# SEC_MMR0_BOOT_CTRL register map
Vendor: Texas Instruments
Peripheral module from a debugger description file (folder J7ES).
Registers are 32-bit, access per field, reset 0x0 unless marked. A register's access mark holds for its fields unless they carry their own. Offsets are as the file gives them; lines under a group give offsets from that group; [hi:lo] are bit positions; {n}, {i} and the like mark numbered series; 'fields as' and 'values as' point back to an identical list; <NAME> marks a mode.

## SEC_MMR0_BOOT_CTRL
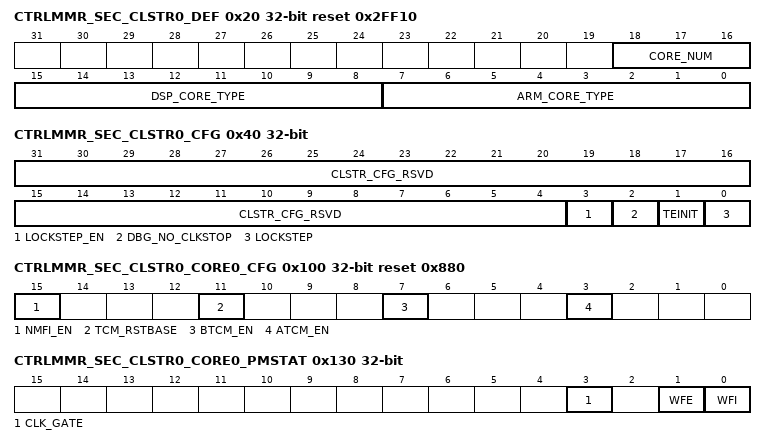
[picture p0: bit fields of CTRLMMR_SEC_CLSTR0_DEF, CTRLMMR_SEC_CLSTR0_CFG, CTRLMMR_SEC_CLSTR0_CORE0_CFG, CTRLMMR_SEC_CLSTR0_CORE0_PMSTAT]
0x20 CTRLMMR_SEC_CLSTR0_DEF ro reset 0x2FF10 — Defines the type of the processor cluster.
  [18:16] CORE_NUM — Number of cores in cluster
  [15:8] DSP_CORE_TYPE — DSP core type configuration. Not shown values are reserved. 0h - C7x 1h - C6x FFh - Not DSP
  [7:0] ARM_CORE_TYPE — ARM core type configuration. Not shown values are reserved. 0h - A53 1h - A57 10h - R5 FFh - Not ARM
0x40 CTRLMMR_SEC_CLSTR0_CFG (reset mask 0xFFFFFFF6) — Configures cluster level characteristics.
  [31:4] CLSTR_CFG_RSVD rw — Reserved for future use. Write '0' to ensure compatibility with future devices.
  [3] LOCKSTEP_EN ro — Lockstep enable. Indicates if R5 lockstep operation is supported on the device
  [2] DBG_NO_CLKSTOP rw — CPU clockstop behavior
  [1] TEINIT rw — Exception handling state at reset:
  [0] LOCKSTEP rw — When set, Core0 and Core1 operate in lockstep mode. Can only be changed if lockstep operation is supported as indicated by CLSTR0_CFG_lockstep_en = 1. If CLSTR0_CFG_lockstep_en = 0, lockstep is not supported, this bit will be read only with a value of 0.
0x100 CTRLMMR_SEC_CLSTR0_CORE0_CFG reset 0x880 — Configures the TCM and interrupt operation of R5 Core0.
  [15] NMFI_EN rw — Enable Core0 Non-Maskable Fast Interrupts when set
  [11] TCM_RSTBASE rw — Core0 A/BTCM Reset Base Address Indicator
  [7] BTCM_EN rw — Enable Core0 BTCM RAM at reset when set
  [3] ATCM_EN rw — Enable Core0 ATCM RAM at reset when set
0x110 CTRLMMR_SEC_CLSTR0_CORE0_BOOTVECT_LO reset 0x200 — Contains the lower 32 bits of the boot vector location for R5 Core0. Bits 4:0 are not used and are always 0.
  [31:7] VECT_ADDR rw — Specifies the lower 25 bits of the 41-bit vector address corresponding to Vector Table address bits[31:7]. Note bits 6:0 of the Vector Table address are always 0.
0x114 CTRLMMR_SEC_CLSTR0_CORE0_BOOTVECT_HI — Contains the lower 16 bits of the boot vector location for R5 Core0.
  [15:0] VECT_ADDR rw — Specifies the upper 16 bits of the 41-bit vector address corresponding to Vector Table address bits[47:32].
0x120 CTRLMMR_SEC_CLSTR0_CORE0_PMCTRL — Configures Cluster Core0 power state.
  [0] CORE_HALT rw — Halt Core0.When 0, indicates that Core0 is in the Halt state.
0x130 CTRLMMR_SEC_CLSTR0_CORE0_PMSTAT ro (reset mask 0xFFFFFFF4) — Shows Cluster Core0 power status.
  [3] CLK_GATE — Core0 Clock StoppedWhen 0, indicates clock stopped due to WFI or WFE state
  [1] WFE — Core0 WFE
  [0] WFI — Core0 WFI
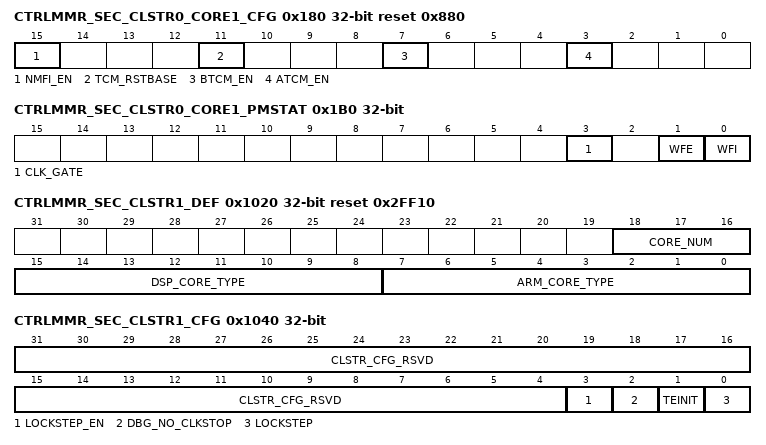
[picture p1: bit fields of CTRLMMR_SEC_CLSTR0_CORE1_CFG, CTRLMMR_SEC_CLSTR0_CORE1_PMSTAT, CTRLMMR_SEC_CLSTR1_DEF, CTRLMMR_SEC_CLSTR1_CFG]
0x180 CTRLMMR_SEC_CLSTR0_CORE1_CFG reset 0x880 — Configures the TCM and interrupt operation of R5 Core1.
  [15] NMFI_EN rw — Enable Core1 Non-Maskable Fast Interrupts when set
  [11] TCM_RSTBASE rw — Core1 A/BTCM Reset Base Address Indicator
  [7] BTCM_EN rw — Enable Core1 BTCM RAM at reset when set
  [3] ATCM_EN rw — Enable Core1 ATCM RAM at reset when set
0x190 CTRLMMR_SEC_CLSTR0_CORE1_BOOTVECT_LO reset 0x200 — Contains the lower 32 bits of the boot vector location for R5 Core1. Bits 4:0 are not used and are always 0.
  fields as CTRLMMR_SEC_CLSTR0_CORE0_BOOTVECT_LO
0x194 CTRLMMR_SEC_CLSTR0_CORE1_BOOTVECT_HI — Contains the lower 16 bits of the boot vector location for R5 Core1.
  fields as CTRLMMR_SEC_CLSTR0_CORE0_BOOTVECT_HI
0x1A0 CTRLMMR_SEC_CLSTR0_CORE1_PMCTRL — Configures Cluster Core1 power state.
  [0] CORE_HALT rw — Halt Core1.When 0, indicates that Core1 is in the Halt state.
0x1B0 CTRLMMR_SEC_CLSTR0_CORE1_PMSTAT ro (reset mask 0xFFFFFFF4) — Shows Cluster Core1 power status.
  [3] CLK_GATE — Core1 Clock StoppedWhen 0, indicates clock stopped due to WFI or WFE state
  [1] WFE — Core1 WFE
  [0] WFI — Core1 WFI
0x1020 CTRLMMR_SEC_CLSTR1_DEF ro reset 0x2FF10 — Defines the type of the processor cluster.
  fields as CTRLMMR_SEC_CLSTR0_DEF
0x1040 CTRLMMR_SEC_CLSTR1_CFG (reset mask 0xFFFFFFF6) — Configures cluster level characteristics.
  [31:4] CLSTR_CFG_RSVD rw — Reserved for future use. Write '0' to ensure compatibility with future devices.
  [3] LOCKSTEP_EN ro — Lockstep enable. Indicates if R5 lockstep operation is supported on the device
  [2] DBG_NO_CLKSTOP rw — CPU clockstop behavior
  [1] TEINIT rw — Exception handling state at reset:
  [0] LOCKSTEP rw — When set, Core0 and Core1 operate in lockstep mode. Can only be changed if lockstep operation is supported as indicated by CLSTR1_CFG_lockstep_en = 1. If CLSTR1_CFG_lockstep_en = 0, lockstep is not supported, this bit will be read only with a value of 0.
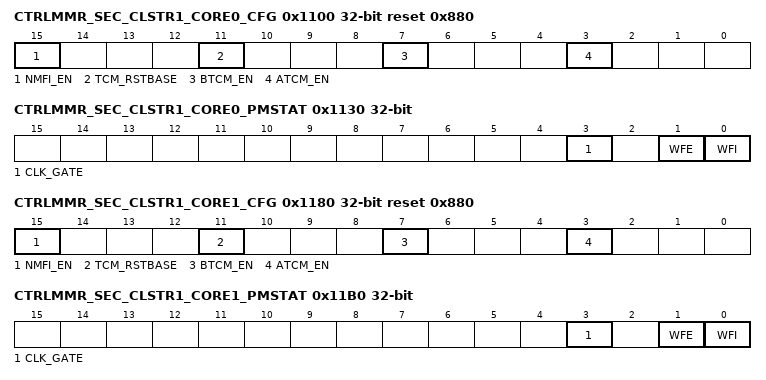
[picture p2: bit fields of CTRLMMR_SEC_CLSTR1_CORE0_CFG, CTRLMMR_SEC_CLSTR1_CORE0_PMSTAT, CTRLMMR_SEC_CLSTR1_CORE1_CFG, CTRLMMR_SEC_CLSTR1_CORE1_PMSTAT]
0x1100 CTRLMMR_SEC_CLSTR1_CORE0_CFG reset 0x880 — Configures the TCM and interrupt operation of R5 Core0.
  fields as CTRLMMR_SEC_CLSTR0_CORE0_CFG
0x1110 CTRLMMR_SEC_CLSTR1_CORE0_BOOTVECT_LO reset 0x200 — Contains the lower 32 bits of the boot vector location for R5 Core0. Bits 4:0 are not used and are always 0.
  fields as CTRLMMR_SEC_CLSTR0_CORE0_BOOTVECT_LO
0x1114 CTRLMMR_SEC_CLSTR1_CORE0_BOOTVECT_HI — Contains the lower 16 bits of the boot vector location for R5 Core0.
  fields as CTRLMMR_SEC_CLSTR0_CORE0_BOOTVECT_HI
0x1120 CTRLMMR_SEC_CLSTR1_CORE0_PMCTRL — Configures Cluster Core0 power state.
  fields as CTRLMMR_SEC_CLSTR0_CORE0_PMCTRL
0x1130 CTRLMMR_SEC_CLSTR1_CORE0_PMSTAT ro (reset mask 0xFFFFFFF4) — Shows Cluster Core0 power status.
  fields as CTRLMMR_SEC_CLSTR0_CORE0_PMSTAT
0x1180 CTRLMMR_SEC_CLSTR1_CORE1_CFG reset 0x880 — Configures the TCM and interrupt operation of R5 Core1.
  fields as CTRLMMR_SEC_CLSTR0_CORE1_CFG
0x1190 CTRLMMR_SEC_CLSTR1_CORE1_BOOTVECT_LO reset 0x200 — Contains the lower 32 bits of the boot vector location for R5 Core1. Bits 4:0 are not used and are always 0.
  fields as CTRLMMR_SEC_CLSTR0_CORE0_BOOTVECT_LO
0x1194 CTRLMMR_SEC_CLSTR1_CORE1_BOOTVECT_HI — Contains the lower 16 bits of the boot vector location for R5 Core1.
  fields as CTRLMMR_SEC_CLSTR0_CORE0_BOOTVECT_HI
0x11A0 CTRLMMR_SEC_CLSTR1_CORE1_PMCTRL — Configures Cluster Core1 power state.
  fields as CTRLMMR_SEC_CLSTR0_CORE1_PMCTRL
0x11B0 CTRLMMR_SEC_CLSTR1_CORE1_PMSTAT ro (reset mask 0xFFFFFFF4) — Shows Cluster Core1 power status.
  fields as CTRLMMR_SEC_CLSTR0_CORE1_PMSTAT
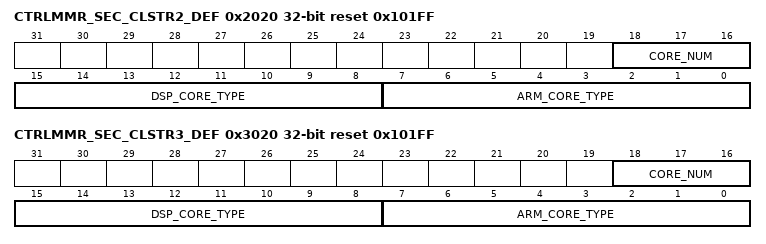
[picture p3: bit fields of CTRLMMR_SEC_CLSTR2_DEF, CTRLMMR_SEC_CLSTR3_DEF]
0x2020 CTRLMMR_SEC_CLSTR2_DEF ro reset 0x101FF — Defines the type of the processor cluster.
  fields as CTRLMMR_SEC_CLSTR0_DEF
0x2040 CTRLMMR_SEC_CLSTR2_CFG — Configures cluster level characteristics.
  [1:0] SSCLK_MODE rw — Controls the C66 clock rate for cluster logic and bus interfaces 0h - Div2 clock mode 1h - Div3 clock mode 2h - Div4 clock mode3h - Reserved
0x2100 CTRLMMR_SEC_CLSTR2_CORE0_CFG — Configures the C66 operation.
  [16] BIG_ENDIAN rw — When big endian operation is selected, C66 core operates in big endian and corepac bridges will swzzle the data in from and out to the SoC (which is always little endian)
0x2110 CTRLMMR_SEC_CLSTR2_CORE0_BOOTVECT_LO reset 0x2000 — Contains the boot vector for the C66 core.
  [21:0] GEM_ISTP_RST_VAL rw — C66 interrupt service table pointer
0x3020 CTRLMMR_SEC_CLSTR3_DEF ro reset 0x101FF — Defines the type of the processor cluster.
  fields as CTRLMMR_SEC_CLSTR0_DEF
0x3040 CTRLMMR_SEC_CLSTR3_CFG — Configures cluster level characteristics.
  fields as CTRLMMR_SEC_CLSTR2_CFG
0x3100 CTRLMMR_SEC_CLSTR3_CORE0_CFG — Configures the C66 operation.
  fields as CTRLMMR_SEC_CLSTR2_CORE0_CFG
0x3110 CTRLMMR_SEC_CLSTR3_CORE0_BOOTVECT_LO reset 0x2000 — Contains the boot vector for the C66 core.
  [21:0] GEM_ISTP_RST_VAL rw — C66 interrupt service table pointer
